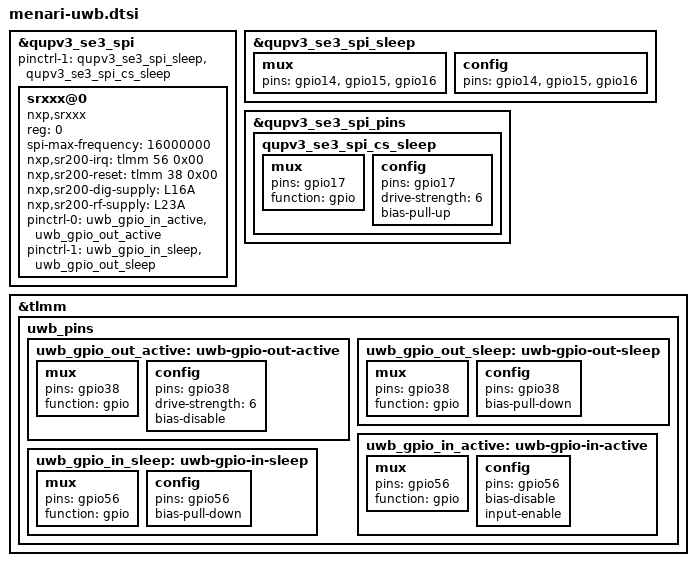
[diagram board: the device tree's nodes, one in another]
// SPDX-License-Identifier: GPL-2.0

&qupv3_se3_spi {
	#address-cells = <1>;
	#size-cells = <0>;

	status = "ok";
	pinctrl-1 = <&qupv3_se3_spi_sleep>, <&qupv3_se3_spi_cs_sleep>;
	srxxx@0 {
		compatible = "nxp,srxxx";
		status = "ok";
		reg = <0>;
		spi-max-frequency = <16000000>;
		nxp,sr200-irq = <&tlmm 56 0x00>;
		nxp,sr200-reset = <&tlmm 38 0x00>;
		nxp,sr200-dig-supply = <&L16A>;
		nxp,sr200-rf-supply = <&L23A>;
		pinctrl-names = "default", "sleep";
		pinctrl-0  = <&uwb_gpio_in_active &uwb_gpio_out_active>;
		pinctrl-1  = <&uwb_gpio_in_sleep &uwb_gpio_out_sleep>;
	};
};

&qupv3_se3_spi_sleep {
	mux {
		pins = "gpio14", "gpio15", "gpio16";
	};

	config {
		pins = "gpio14", "gpio15", "gpio16";
	};
};

&qupv3_se3_spi_pins {
	qupv3_se3_spi_cs_sleep: qupv3_se3_spi_cs_sleep {
		mux {
			pins = "gpio17";
			function = "gpio";
		};

		config {
			pins = "gpio17";
			drive-strength = <6>;
			bias-pull-up;
		};
	};
};

&tlmm {
	uwb_pins {
		uwb_gpio_out_active: uwb-gpio-out-active {
			mux {
				pins = "gpio38";
				function = "gpio";
			};
			config {
				pins = "gpio38";
				drive-strength = <6>;
				bias-disable;
			};
		};
		uwb_gpio_out_sleep: uwb-gpio-out-sleep {
			mux {
				pins = "gpio38";
				function = "gpio";
			};
			config {
				pins = "gpio38";
				bias-pull-down;
			};
		};
		uwb_gpio_in_active: uwb-gpio-in-active {
			mux {
				pins = "gpio56";
				function = "gpio";
			};
			config {
				pins = "gpio56";
				bias-disable;
				input-enable;
			};
		};
		uwb_gpio_in_sleep: uwb-gpio-in-sleep {
			mux {
				pins = "gpio56";
				function = "gpio";
			};
			config {
				pins = "gpio56";
				bias-pull-down;
			};
		};
	};
};
